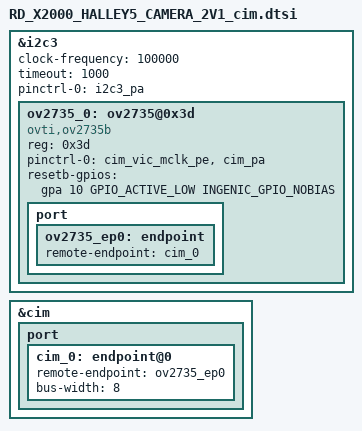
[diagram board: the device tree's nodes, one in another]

&i2c3 {
	status = "okay";
	clock-frequency = <100000>;
	timeout = <1000>;
	pinctrl-names = "default";
	pinctrl-0 = <&i2c3_pa>;

	ov2735_0:ov2735@0x3d {
		status = "ok";
		compatible = "ovti,ov2735b";
		reg = <0x3d>;
		pinctrl-names = "default","cim";
		pinctrl-0 = <&cim_vic_mclk_pe>, <&cim_pa>;

		resetb-gpios = <&gpa 10 GPIO_ACTIVE_LOW INGENIC_GPIO_NOBIAS>;

		port {
			ov2735_ep0:endpoint {
				remote-endpoint = <&cim_0>;
			};
		};
	};

};

&cim {
	status = "okay";
	port {
		cim_0: endpoint@0 {
			remote-endpoint = <&ov2735_ep0>;
			bus-width = <8>;
		};
	};
};

